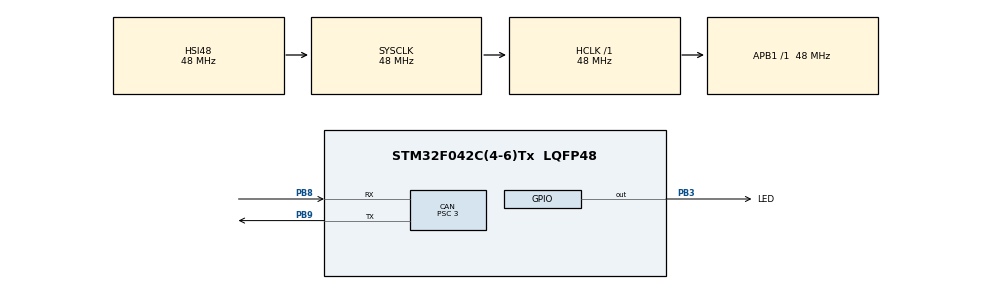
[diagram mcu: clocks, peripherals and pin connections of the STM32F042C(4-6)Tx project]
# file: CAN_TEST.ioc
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CAN.BS1=CAN_BS1_13TQ
CAN.BS2=CAN_BS2_2TQ
CAN.CalculateTimeQuantum=62.5
CAN.Prescaler=3
CAN.SJW=CAN_SJW_1TQ
Mcu.Family=STM32F0
Mcu.Name=STM32F042C(4-6)Tx
Mcu.Package=LQFP48
NVIC.CEC_CAN_IRQn=true\:0\:0\:false\:false\:true\:true\:true
PA13.Mode=Serial_Wire
PA13.Signal=SYS_SWDIO
PA14.Mode=Serial_Wire
PA14.Signal=SYS_SWCLK
PB3.GPIO_Label=LED
PB3.GPIO_ModeDefaultOutputPP=GPIO_MODE_OUTPUT_PP
PB3.GPIO_PuPd=GPIO_NOPULL
PB3.GPIO_Speed=GPIO_SPEED_FREQ_HIGH
PB3.PinState=GPIO_PIN_RESET
PB3.Signal=GPIO_Output
PB8.Mode=Master
PB8.Signal=CAN_RX
PB9.Mode=Master
PB9.Signal=CAN_TX
ProjectManager.HeapSize=0x200
ProjectManager.StackSize=0x400
ProjectManager.TargetToolchain=STM32CubeIDE
RCC.AHBFreq_Value=48000000
RCC.APB1Freq_Value=48000000
RCC.APB1TimFreq_Value=48000000
RCC.HCLKFreq_Value=48000000
RCC.SYSCLKFreq_VALUE=48000000
RCC.SYSCLKSource=RCC_SYSCLKSOURCE_HSI48
board=custom

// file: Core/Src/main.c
/* USER CODE BEGIN Header */
/**
 ******************************************************************************
 * @file           : main.c
 * @brief          : Main program body
 ******************************************************************************
 * @attention
 *
 * <h2><center>&copy; Copyright (c) 2020 STMicroelectronics.
 * All rights reserved.</center></h2>
 *
 * This software component is licensed by ST under BSD 3-Clause license,
 * the "License"; You may not use this file except in compliance with the
 * License. You may obtain a copy of the License at:
 *                        opensource.org/licenses/BSD-3-Clause
 *
 ******************************************************************************
 */
/* USER CODE END Header */
#include "main.h"

/* USER CODE BEGIN PTD */

CAN_RxHeaderTypeDef canRxHeader;
CAN_TxHeaderTypeDef canTxHeader;

uint8_t canRxData[8]; // ���Ź���
uint8_t canTxData[8]; // �۽Ź���
uint32_t canTxMailBox;

int sendCnt = 0;
/* USER CODE END PTD */

CAN_HandleTypeDef hcan;

void SystemClock_Config(void);
static void MX_GPIO_Init(void);
static void MX_CAN_Init(void);

/* USER CODE BEGIN 0 */

void CAN1_User_Init(void) {

	CAN_FilterTypeDef canFilter;

	canFilter.FilterBank = 0;
	canFilter.FilterMode = CAN_FILTERMODE_IDMASK;
	canFilter.FilterScale = CAN_FILTERSCALE_32BIT;
	canFilter.FilterIdHigh = 0x0000 << 5;
	canFilter.FilterIdLow = 0x0000;
	canFilter.FilterMaskIdHigh = 0x0000 << 5;
	canFilter.FilterMaskIdLow = 0x0000;
	canFilter.FilterFIFOAssignment = 0;
	canFilter.FilterActivation = ENABLE;
	canFilter.SlaveStartFilterBank = 0;

	if (HAL_CAN_ConfigFilter(&hcan, &canFilter) != HAL_OK) {
		Error_Handler();
	}

	canTxHeader.StdId = 0x01;
	canTxHeader.ExtId = 0x01;
	canTxHeader.RTR = CAN_RTR_DATA;
	canTxHeader.IDE = CAN_ID_STD;
	canTxHeader.DLC = 8;
}

void CAN1_Tx(void) {
	canTxMailBox = HAL_CAN_GetTxMailboxesFreeLevel(&hcan);
	for (int i = 0; i < 8; i++) {
		canTxData[i] = i + 1;
	}
	HAL_CAN_AddTxMessage(&hcan, &canTxHeader, canTxData, &canTxMailBox);
}

void HAL_CAN_RxFifo0MsgPendingCallback(CAN_HandleTypeDef *hcan) {

	canRxHeader.StdId = 0;         //clear
	HAL_CAN_GetRxMessage(hcan, CAN_RX_FIFO0, &canRxHeader, &canRxData[0]);
	HAL_GPIO_TogglePin(LED_GPIO_Port, LED_Pin);
}

/* USER CODE END 0 */

int main(void) {

	/* MCU Configuration--------------------------------------------------------*/

	/* Reset of all peripherals, Initializes the Flash interface and the Systick. */
	HAL_Init();

	/* Configure the system clock */
	SystemClock_Config();

	/* Initialize all configured peripherals */
	MX_GPIO_Init();
	MX_CAN_Init();
	/* USER CODE BEGIN 2 */

	HAL_CAN_Start(&hcan);
	CAN1_User_Init();
	HAL_CAN_ActivateNotification(&hcan,
	CAN_IT_RX_FIFO0_MSG_PENDING | CAN_IT_RX_FIFO1_MSG_PENDING);

	/* USER CODE END 2 */

	/* Infinite loop */
	/* USER CODE BEGIN WHILE */
	while (1) {
		CAN1_Tx();
		/* USER CODE END WHILE */

		/* USER CODE BEGIN 3 */

		HAL_Delay(100);
	}
	/* USER CODE END 3 */
}

void SystemClock_Config(void) {
	RCC_OscInitTypeDef RCC_OscInitStruct = { 0 };
	RCC_ClkInitTypeDef RCC_ClkInitStruct = { 0 };

	/** Initializes the RCC Oscillators according to the specified parameters
	 * in the RCC_OscInitTypeDef structure.
	 */
	RCC_OscInitStruct.OscillatorType = RCC_OSCILLATORTYPE_HSI48;
	RCC_OscInitStruct.HSI48State = RCC_HSI48_ON;
	RCC_OscInitStruct.PLL.PLLState = RCC_PLL_NONE;
	if (HAL_RCC_OscConfig(&RCC_OscInitStruct) != HAL_OK) {
		Error_Handler();
	}
	/** Initializes the CPU, AHB and APB buses clocks
	 */
	RCC_ClkInitStruct.ClockType = RCC_CLOCKTYPE_HCLK | RCC_CLOCKTYPE_SYSCLK
			| RCC_CLOCKTYPE_PCLK1;
	RCC_ClkInitStruct.SYSCLKSource = RCC_SYSCLKSOURCE_HSI48;
	RCC_ClkInitStruct.AHBCLKDivider = RCC_SYSCLK_DIV1;
	RCC_ClkInitStruct.APB1CLKDivider = RCC_HCLK_DIV1;

	if (HAL_RCC_ClockConfig(&RCC_ClkInitStruct, FLASH_LATENCY_1) != HAL_OK) {
		Error_Handler();
	}
}

static void MX_CAN_Init(void) {

	hcan.Instance = CAN;
	hcan.Init.Prescaler = 3;
	hcan.Init.Mode = CAN_MODE_NORMAL;
	hcan.Init.SyncJumpWidth = CAN_SJW_1TQ;
	hcan.Init.TimeSeg1 = CAN_BS1_13TQ;
	hcan.Init.TimeSeg2 = CAN_BS2_2TQ;
	hcan.Init.TimeTriggeredMode = DISABLE;
	hcan.Init.AutoBusOff = DISABLE;
	hcan.Init.AutoWakeUp = DISABLE;
	hcan.Init.AutoRetransmission = DISABLE;
	hcan.Init.ReceiveFifoLocked = DISABLE;
	hcan.Init.TransmitFifoPriority = DISABLE;
	if (HAL_CAN_Init(&hcan) != HAL_OK) {
		Error_Handler();
	}

}

static void MX_GPIO_Init(void) {
	GPIO_InitTypeDef GPIO_InitStruct = { 0 };

	/* GPIO Ports Clock Enable */
	__HAL_RCC_GPIOA_CLK_ENABLE();
	__HAL_RCC_GPIOB_CLK_ENABLE();

	/*Configure GPIO pin Output Level */
	HAL_GPIO_WritePin(LED_GPIO_Port, LED_Pin, GPIO_PIN_RESET);

	/*Configure GPIO pin : LED_Pin */
	GPIO_InitStruct.Pin = LED_Pin;
	GPIO_InitStruct.Mode = GPIO_MODE_OUTPUT_PP;
	GPIO_InitStruct.Pull = GPIO_NOPULL;
	GPIO_InitStruct.Speed = GPIO_SPEED_FREQ_HIGH;
	HAL_GPIO_Init(LED_GPIO_Port, &GPIO_InitStruct);

}

void Error_Handler(void) {
}

/************************ (C) COPYRIGHT STMicroelectronics *****END OF FILE****/
